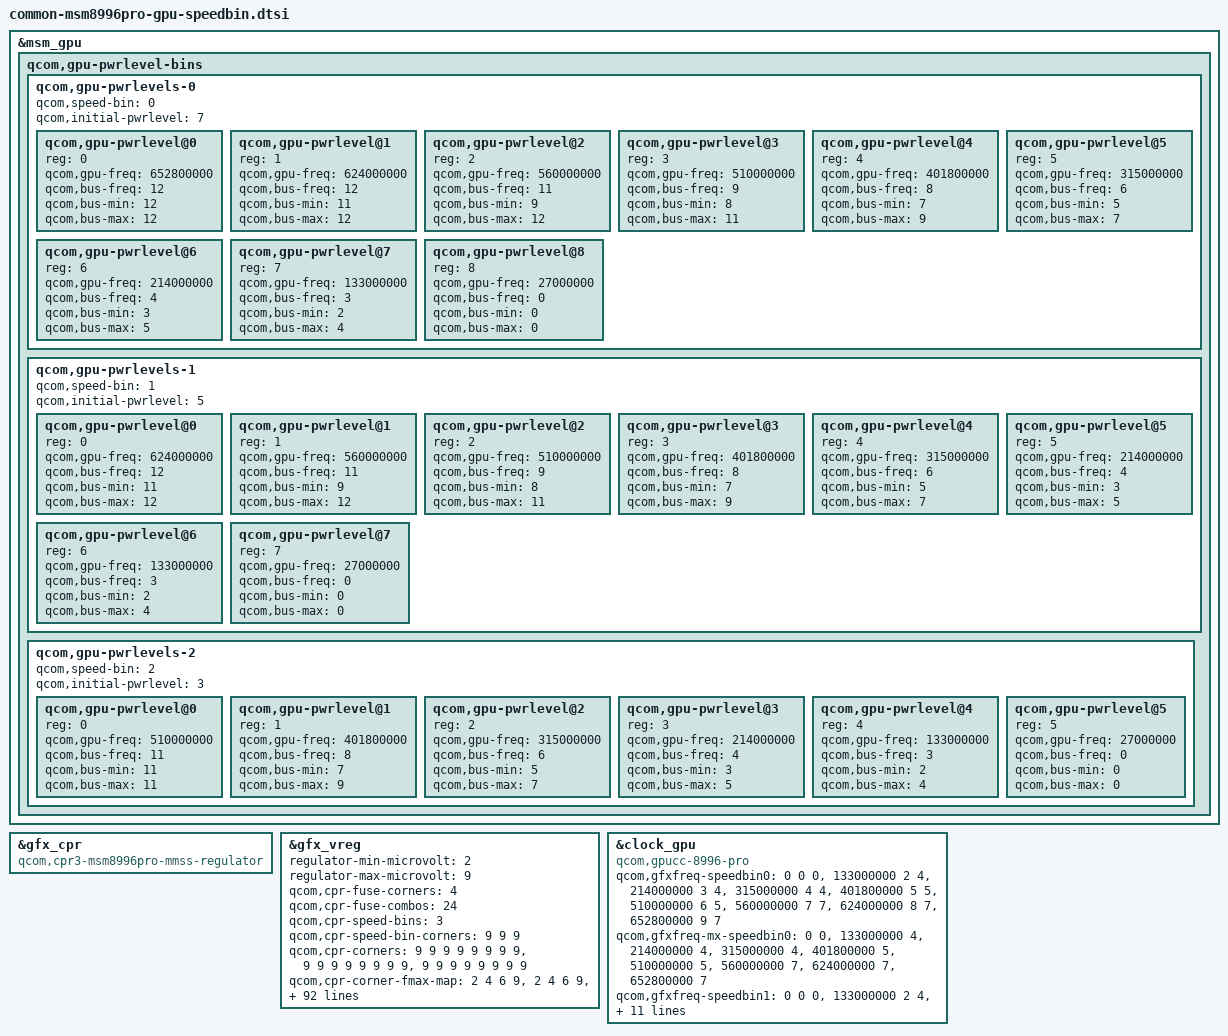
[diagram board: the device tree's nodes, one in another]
&msm_gpu {
	qcom,gpu-pwrlevel-bins {
		qcom,gpu-pwrlevels-0 {
			#address-cells = <1>;
			#size-cells = <0>;

			qcom,speed-bin = <0>;

			qcom,initial-pwrlevel = <7>;

			qcom,gpu-pwrlevel@0 {
				reg = <0>;
				qcom,gpu-freq = <652800000>;
				qcom,bus-freq = <12>;
				qcom,bus-min = <12>;
				qcom,bus-max = <12>;
			};

			qcom,gpu-pwrlevel@1 {
				reg = <1>;
				qcom,gpu-freq = <624000000>;
				qcom,bus-freq = <12>;
				qcom,bus-min = <11>;
				qcom,bus-max = <12>;
			};

			qcom,gpu-pwrlevel@2 {
				reg = <2>;
				qcom,gpu-freq = <560000000>;
				qcom,bus-freq = <11>;
				qcom,bus-min = <9>;
				qcom,bus-max = <12>;
			};

			qcom,gpu-pwrlevel@3 {
				reg = <3>;
				qcom,gpu-freq = <510000000>;
				qcom,bus-freq = <9>;
				qcom,bus-min = <8>;
				qcom,bus-max = <11>;
			};

			qcom,gpu-pwrlevel@4 {
				reg = <4>;
				qcom,gpu-freq = <401800000>;
				qcom,bus-freq = <8>;
				qcom,bus-min = <7>;
				qcom,bus-max = <9>;
			};

			qcom,gpu-pwrlevel@5 {
				reg = <5>;
				qcom,gpu-freq = <315000000>;
				qcom,bus-freq = <6>;
				qcom,bus-min = <5>;
				qcom,bus-max = <7>;
			};

			qcom,gpu-pwrlevel@6 {
				reg = <6>;
				qcom,gpu-freq = <214000000>;
				qcom,bus-freq = <4>;
				qcom,bus-min = <3>;
				qcom,bus-max = <5>;
			};

			qcom,gpu-pwrlevel@7 {
				reg = <7>;
				qcom,gpu-freq = <133000000>;
				qcom,bus-freq = <3>;
				qcom,bus-min = <2>;
				qcom,bus-max = <4>;
			};

			qcom,gpu-pwrlevel@8 {
				reg = <8>;
				qcom,gpu-freq = <27000000>;
				qcom,bus-freq = <0>;
				qcom,bus-min = <0>;
				qcom,bus-max = <0>;
			};
		};

		qcom,gpu-pwrlevels-1 {
			#address-cells = <1>;
			#size-cells = <0>;

			qcom,speed-bin = <1>;

			qcom,initial-pwrlevel = <5>;

			qcom,gpu-pwrlevel@0 {
				reg = <0>;
				qcom,gpu-freq = <624000000>;
				qcom,bus-freq = <12>;
				qcom,bus-min = <11>;
				qcom,bus-max = <12>;
			};

			qcom,gpu-pwrlevel@1 {
				reg = <1>;
				qcom,gpu-freq = <560000000>;
				qcom,bus-freq = <11>;
				qcom,bus-min = <9>;
				qcom,bus-max = <12>;
			};

			qcom,gpu-pwrlevel@2 {
				reg = <2>;
				qcom,gpu-freq = <510000000>;
				qcom,bus-freq = <9>;
				qcom,bus-min = <8>;
				qcom,bus-max = <11>;
			};

			qcom,gpu-pwrlevel@3 {
				reg = <3>;
				qcom,gpu-freq = <401800000>;
				qcom,bus-freq = <8>;
				qcom,bus-min = <7>;
				qcom,bus-max = <9>;
			};

			qcom,gpu-pwrlevel@4 {
				reg = <4>;
				qcom,gpu-freq = <315000000>;
				qcom,bus-freq = <6>;
				qcom,bus-min = <5>;
				qcom,bus-max = <7>;
			};

			qcom,gpu-pwrlevel@5 {
				reg = <5>;
				qcom,gpu-freq = <214000000>;
				qcom,bus-freq = <4>;
				qcom,bus-min = <3>;
				qcom,bus-max = <5>;
			};

			qcom,gpu-pwrlevel@6 {
				reg = <6>;
				qcom,gpu-freq = <133000000>;
				qcom,bus-freq = <3>;
				qcom,bus-min = <2>;
				qcom,bus-max = <4>;
			};

			qcom,gpu-pwrlevel@7 {
				reg = <7>;
				qcom,gpu-freq = <27000000>;
				qcom,bus-freq = <0>;
				qcom,bus-min = <0>;
				qcom,bus-max = <0>;
			};
		};

		qcom,gpu-pwrlevels-2 {
			#address-cells = <1>;
			#size-cells = <0>;

			qcom,speed-bin = <2>;

			qcom,initial-pwrlevel = <3>;

			qcom,gpu-pwrlevel@0 {
				reg = <0>;
				qcom,gpu-freq = <510000000>;
				qcom,bus-freq = <11>;
				qcom,bus-min = <11>;
				qcom,bus-max = <11>;
			};

			qcom,gpu-pwrlevel@1 {
				reg = <1>;
				qcom,gpu-freq = <401800000>;
				qcom,bus-freq = <8>;
				qcom,bus-min = <7>;
				qcom,bus-max = <9>;
			};

			qcom,gpu-pwrlevel@2 {
				reg = <2>;
				qcom,gpu-freq = <315000000>;
				qcom,bus-freq = <6>;
				qcom,bus-min = <5>;
				qcom,bus-max = <7>;
			};

			qcom,gpu-pwrlevel@3 {
				reg = <3>;
				qcom,gpu-freq = <214000000>;
				qcom,bus-freq = <4>;
				qcom,bus-min = <3>;
				qcom,bus-max = <5>;
			};

			qcom,gpu-pwrlevel@4 {
				reg = <4>;
				qcom,gpu-freq = <133000000>;
				qcom,bus-freq = <3>;
				qcom,bus-min = <2>;
				qcom,bus-max = <4>;
			};

			qcom,gpu-pwrlevel@5 {
				reg = <5>;
				qcom,gpu-freq = <27000000>;
				qcom,bus-freq = <0>;
				qcom,bus-min = <0>;
				qcom,bus-max = <0>;
			};
		};
	};
};

&gfx_cpr {
	compatible = "qcom,cpr3-msm8996pro-mmss-regulator";
};

&gfx_vreg {
	regulator-min-microvolt = <2>;
	regulator-max-microvolt = <9>;

	qcom,cpr-fuse-corners = <4>;
	qcom,cpr-fuse-combos = <24>;
	qcom,cpr-speed-bins = <3>;
	qcom,cpr-speed-bin-corners = <9 9 9>;
	qcom,cpr-corners =
		/* Speed bin 0 */
		<9 9 9 9 9 9 9 9>,

		/* Speed bin 1 */
		<9 9 9 9 9 9 9 9>,

		/* Speed bin 2 */
		<9 9 9 9 9 9 9 9>;

	qcom,cpr-corner-fmax-map =
		/* Speed bin 0 */
		<2 4 6 9>,

		/* Speed bin 1 */
		<2 4 6 9>,

		/* Speed bin 2 */
		<2 4 6 9>;

	qcom,cpr-voltage-ceiling =
		/* Speed bin 0 */
		<400000  670000  670000  745000  825000  905000  960000 1015000
		1065000>,

		/* Speed bin 1 */
		<400000  670000  670000  745000  825000  905000  960000 1015000
		1065000>,

		/* Speed bin 2 */
		<400000  670000  670000  745000  825000  905000  960000 1015000
		1065000>;

	qcom,cpr-voltage-floor =
		/* Speed bin 0 */
		<400000  520000  520000  520000  520000  520000  520000  520000
		 520000>,

		/* Speed bin 1 */
		<400000  520000  520000  520000  520000  520000  520000  520000
		 520000>,

		/* Speed bin 2 */
		<400000  520000  520000  520000  520000  520000  520000  520000
		 520000>;

	qcom,mem-acc-voltage =
		/* Speed bin 0 */
		<1 1 1 1 2 2 2 2 2>,

		/* Speed bin 1 */
		<1 1 1 1 2 2 2 2 2>,

		/* Speed bin 2 */
		<1 1 1 1 2 2 2 2 2>;

	qcom,corner-frequencies =
		/* Speed bin 0 */
		<0 133000000 214000000 315000000 401800000 510000000 560000000
		   624000000 652800000>,

		/* Speed bin 1 */
		<0 133000000 214000000 315000000 401800000 510000000 560000000
		   624000000 652800000>,

		/* Speed bin 2 */
		<0 133000000 214000000 315000000 401800000 510000000 560000000
		   624000000 652800000>;

	qcom,cpr-target-quotients =
		/* Speed bin 0 */
		<0 0 0 0 0 0    0    0    0    0    0    0 0 0 0 0>,
		<0 0 0 0 0 0  185  179  291  299  304  319 0 0 0 0>,
		<0 0 0 0 0 0  287  273  425  426  443  453 0 0 0 0>,
		<0 0 0 0 0 0  414  392  584  576  608  612 0 0 0 0>,
		<0 0 0 0 0 0  459  431  684  644  692  679 0 0 0 0>,
		<0 0 0 0 0 0  577  543  798  768  823  810 0 0 0 0>,
		<0 0 0 0 0 0  669  629  886  864  924  911 0 0 0 0>,
		<0 0 0 0 0 0  771  725  984  970 1036 1024 0 0 0 0>,
		<0 0 0 0 0 0  908  868 1118 1106 1179 1174 0 0 0 0>,

		/* Speed bin 1 */
		<0 0 0 0 0 0    0    0    0    0    0    0 0 0 0 0>,
		<0 0 0 0 0 0  185  179  291  299  304  319 0 0 0 0>,
		<0 0 0 0 0 0  287  273  425  426  443  453 0 0 0 0>,
		<0 0 0 0 0 0  414  392  584  576  608  612 0 0 0 0>,
		<0 0 0 0 0 0  459  431  684  644  692  679 0 0 0 0>,
		<0 0 0 0 0 0  577  543  798  768  823  810 0 0 0 0>,
		<0 0 0 0 0 0  669  629  886  864  924  911 0 0 0 0>,
		<0 0 0 0 0 0  771  725  984  970 1036 1024 0 0 0 0>,
		<0 0 0 0 0 0  908  868 1118 1106 1179 1174 0 0 0 0>,

		/* Speed bin 2 */
		<0 0 0 0 0 0    0    0    0    0    0    0 0 0 0 0>,
		<0 0 0 0 0 0  185  179  291  299  304  319 0 0 0 0>,
		<0 0 0 0 0 0  287  273  425  426  443  453 0 0 0 0>,
		<0 0 0 0 0 0  414  392  584  576  608  612 0 0 0 0>,
		<0 0 0 0 0 0  459  431  684  644  692  679 0 0 0 0>,
		<0 0 0 0 0 0  577  543  798  768  823  810 0 0 0 0>,
		<0 0 0 0 0 0  669  629  886  864  924  911 0 0 0 0>,
		<0 0 0 0 0 0  771  725  984  970 1036 1024 0 0 0 0>,
		<0 0 0 0 0 0  908  868 1118 1106 1179 1174 0 0 0 0>;

	qcom,cpr-ro-scaling-factor =
		/* Speed bin 0 */
		<0 0 0 0 0 0 2035 1917 1959 2131 2246 2253 0 0 0 0>,
		<0 0 0 0 0 0 2035 1917 1959 2131 2246 2253 0 0 0 0>,
		<0 0 0 0 0 0 2035 1917 1959 2131 2246 2253 0 0 0 0>,
		<0 0 0 0 0 0 2035 1917 1959 2131 2246 2253 0 0 0 0>,
		<0 0 0 0 0 0 2035 1917 1959 2131 2246 2253 0 0 0 0>,
		<0 0 0 0 0 0 2035 1917 1959 2131 2246 2253 0 0 0 0>,
		<0 0 0 0 0 0 2035 1917 1959 2131 2246 2253 0 0 0 0>,
		<0 0 0 0 0 0 2035 1917 1959 2131 2246 2253 0 0 0 0>,
		<0 0 0 0 0 0 2035 1917 1959 2131 2246 2253 0 0 0 0>,

		/* Speed bin 1 */
		<0 0 0 0 0 0 2035 1917 1959 2131 2246 2253 0 0 0 0>,
		<0 0 0 0 0 0 2035 1917 1959 2131 2246 2253 0 0 0 0>,
		<0 0 0 0 0 0 2035 1917 1959 2131 2246 2253 0 0 0 0>,
		<0 0 0 0 0 0 2035 1917 1959 2131 2246 2253 0 0 0 0>,
		<0 0 0 0 0 0 2035 1917 1959 2131 2246 2253 0 0 0 0>,
		<0 0 0 0 0 0 2035 1917 1959 2131 2246 2253 0 0 0 0>,
		<0 0 0 0 0 0 2035 1917 1959 2131 2246 2253 0 0 0 0>,
		<0 0 0 0 0 0 2035 1917 1959 2131 2246 2253 0 0 0 0>,
		<0 0 0 0 0 0 2035 1917 1959 2131 2246 2253 0 0 0 0>,

		/* Speed bin 2 */
		<0 0 0 0 0 0 2035 1917 1959 2131 2246 2253 0 0 0 0>,
		<0 0 0 0 0 0 2035 1917 1959 2131 2246 2253 0 0 0 0>,
		<0 0 0 0 0 0 2035 1917 1959 2131 2246 2253 0 0 0 0>,
		<0 0 0 0 0 0 2035 1917 1959 2131 2246 2253 0 0 0 0>,
		<0 0 0 0 0 0 2035 1917 1959 2131 2246 2253 0 0 0 0>,
		<0 0 0 0 0 0 2035 1917 1959 2131 2246 2253 0 0 0 0>,
		<0 0 0 0 0 0 2035 1917 1959 2131 2246 2253 0 0 0 0>,
		<0 0 0 0 0 0 2035 1917 1959 2131 2246 2253 0 0 0 0>,
		<0 0 0 0 0 0 2035 1917 1959 2131 2246 2253 0 0 0 0>;

	qcom,cpr-open-loop-voltage-fuse-adjustment =
		/* Speed bin 0 */
		<(-85000) (-15000) (-15000) (-40000)>,

		/* Speed bin 1 */
		<(-85000) (-15000) (-15000) (-40000)>,

		/* Speed bin 2 */
		<(-85000) (-15000) (-15000) (-40000)>;

	qcom,cpr-closed-loop-voltage-adjustment =
		/* Speed bin 0 */
		<0 0 30000 10000 10000 45000 25000 25000 (-35000)>,

		/* Speed bin 1 */
		<0 0 30000 10000 10000 45000 25000 25000 (-35000)>,

		/* Speed bin 2 */
		<0 0 30000 10000 10000 45000 25000 25000 (-35000)>;

	qcom,cpr-floor-to-ceiling-max-range =
		/* Speed bin 0 */
		<0 70000 70000 75000 80000 90000 95000 100000 100000>,

		/* Speed bin 1 */
		<0 70000 70000 75000 80000 90000 95000 100000 100000>,

		/* Speed bin 2 */
		<0 70000 70000 75000 80000 90000 95000 100000 100000>;

	qcom,cpr-fused-closed-loop-voltage-adjustment-map =
		/* Speed bin 0 */
		<0 2 2 2 2 0 0 4 4>,

		/* Speed bin 1 */
		<0 2 2 2 2 0 0 4 4>,

		/* Speed bin 2 */
		<0 2 2 2 2 0 0 4 4>;

	qcom,cpr-aging-max-voltage-adjustment = <15000>;
	qcom,cpr-aging-ref-corner = <6>;
	qcom,cpr-aging-ro-scaling-factor = <2950>;
	qcom,allow-aging-voltage-adjustment = <1>;
	qcom,allow-aging-open-loop-voltage-adjustment = <1>;
};

&clock_gpu {
	compatible = "qcom,gpucc-8996-pro";
	qcom,gfxfreq-speedbin0 =
		<	   0  0  0 >,
		<  133000000  2  4 >,
		<  214000000  3  4 >,
		<  315000000  4  4 >,
		<  401800000  5  5 >,
		<  510000000  6  5 >,
		<  560000000  7  7 >,
		<  624000000  8  7 >,
		<  652800000  9  7 >;
	qcom,gfxfreq-mx-speedbin0 =
		<	   0  0 >,
		<  133000000  4 >,
		<  214000000  4 >,
		<  315000000  4 >,
		<  401800000  5 >,
		<  510000000  5 >,
		<  560000000  7 >,
		<  624000000  7 >,
		<  652800000  7 >;

	qcom,gfxfreq-speedbin1 =
		<	   0  0  0 >,
		<  133000000  2  4 >,
		<  214000000  3  4 >,
		<  315000000  4  4 >,
		<  401800000  5  5 >,
		<  510000000  6  5 >,
		<  560000000  7  7 >,
		<  624000000  8  7 >;
	qcom,gfxfreq-mx-speedbin1 =
		<	   0  0 >,
		<  133000000  4 >,
		<  214000000  4 >,
		<  315000000  4 >,
		<  401800000  5 >,
		<  510000000  5 >,
		<  560000000  7 >,
		<  624000000  7 >;
	qcom,gfxfreq-speedbin2 =
		<          0  0  0 >,
		<  133000000  2  4 >,
		<  214000000  3  4 >,
		<  315000000  4  4 >,
		<  401800000  5  5 >,
		<  510000000  6  5 >;
	qcom,gfxfreq-mx-speedbin2 =
		<          0  0 >,
		<  133000000  4 >,
		<  214000000  4 >,
		<  315000000  4 >,
		<  401800000  5 >,
		<  510000000  5 >;
};
